AUTOSAR XML (schema 00050)
package /ara/com/secoc
  std cpp implementation data type VerificationStatusResult: compu {0x00=kSecOcVerificationSuccess, 0x01=kSecOcVerificationFailure, 0x02=kSecOcFreshnessFailure, 0x03=kSecOcAuthenticationBuildFailure, 0x04=kSecOcNoVerification, 0x05=kSecOcVerificationFailureOverwritten}, type-emitter=TYPE_EMITTER_ARA, type-reference=uint8_t
    namespaces:
      symbol props ara_1: symbol=ara
      symbol props com_2: symbol=com
      symbol props secoc_3: symbol=secoc
  std cpp implementation data type OverrideStatus: compu {0x00=kSecOcOverrideDropUntilNotice, 0x01=kSecOcOverrideDropUntilLimit, 0x02=kSecOcOverrideCancel, 0x40=kSecOcOverridePassUntilNotice, 0x41=kSecOcOverrideSkipUntilLimit, 0x42=kSecOcOverridePassUntilLimit, 0x43=kSecOcOverrideSkipUntilNotice}, type-emitter=TYPE_EMITTER_ARA, type-reference=uint8_t
    namespaces:
      symbol props ara_1: symbol=ara
      symbol props com_2: symbol=com
      symbol props secoc_3: symbol=secoc
  std cpp implementation data type VerificationStatusContainer: category=STRUCTURE, type-emitter=TYPE_EMITTER_ARA
    namespaces:
      symbol props ara_1: symbol=ara
      symbol props com_2: symbol=com
      symbol props secoc_3: symbol=secoc
    cpp implementation data type element freshnessValueID: type-reference=uint16_t
    cpp implementation data type element verificationStatus: type-reference=VerificationStatusResult
    cpp implementation data type element secOCDataId: type-reference=uint16_t
  service interface VerificationStatus
    namespaces:
      symbol props ara_1: symbol=ara
      symbol props com_2: symbol=com
      symbol props secoc_3: symbol=secoc
    events:
      data VerificationStatus: type=VerificationStatusContainer
  service interface VerificationStatusConfigurationByDataId
    namespaces:
      symbol props ara_1: symbol=ara
      symbol props com_2: symbol=com
      symbol props secoc_3: symbol=secoc
    methods:
      operation VerifyStatusOverride
        arg dataID: type=uint16_t, direction=IN
        arg overrideStatus: type=OverrideStatus, direction=IN
        arg numberOfMessagesToOverride: type=uint8_t, direction=IN
  service interface VerificationStatusConfigurationByFreshnessId
    namespaces:
      symbol props ara_1: symbol=ara
      symbol props com_2: symbol=com
      symbol props secoc_3: symbol=secoc
    methods:
      operation VerifyStatusOverride
        arg freshnessID: type=uint16_t, direction=IN
        arg overrideStatus: type=OverrideStatus, direction=IN
        arg numberOfMessagesToOverride: type=uint8_t, direction=IN
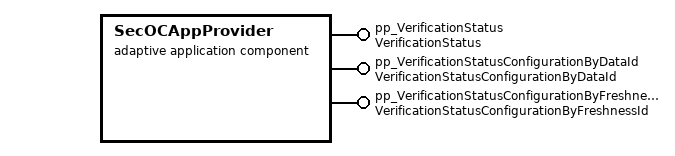
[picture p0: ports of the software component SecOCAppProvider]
  adaptive application sw component type SecOCAppProvider
    provide port pp_VerificationStatus: port-prototype-props=r-port-prototype-props=search-intention=SEARCH-FOR-SPECIFIC-INSTANCE, provided-interface=VerificationStatus
    provide port pp_VerificationStatusConfigurationByDataId: port-prototype-props=r-port-prototype-props=search-intention=SEARCH-FOR-SPECIFIC-INSTANCE, provided-interface=VerificationStatusConfigurationByDataId
    provide port pp_VerificationStatusConfigurationByFreshnessId: port-prototype-props=r-port-prototype-props=search-intention=SEARCH-FOR-SPECIFIC-INSTANCE, provided-interface=VerificationStatusConfigurationByFreshnessId
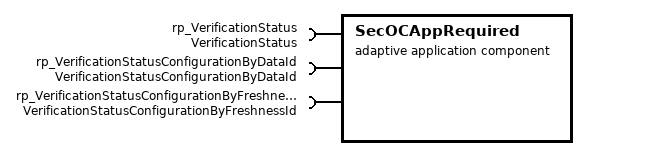
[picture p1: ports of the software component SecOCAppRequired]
  adaptive application sw component type SecOCAppRequired
    require port rp_VerificationStatus: port-prototype-props=r-port-prototype-props=search-intention=SEARCH-FOR-SPECIFIC-INSTANCE, required-interface=VerificationStatus
    require port rp_VerificationStatusConfigurationByDataId: port-prototype-props=r-port-prototype-props=search-intention=SEARCH-FOR-SPECIFIC-INSTANCE, required-interface=VerificationStatusConfigurationByDataId
    require port rp_VerificationStatusConfigurationByFreshnessId: port-prototype-props=r-port-prototype-props=search-intention=SEARCH-FOR-SPECIFIC-INSTANCE, required-interface=VerificationStatusConfigurationByFreshnessId
